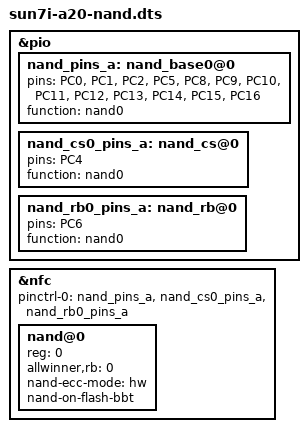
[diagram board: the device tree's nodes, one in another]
/dts-v1/;
/plugin/;

/ {
	fragment@0 {
		target = <&pio>;
		__overlay__ {
			nand_pins_a: nand_base0@0 {
				pins = "PC0", "PC1", "PC2",
					"PC5", "PC8", "PC9", "PC10",
					"PC11", "PC12", "PC13", "PC14",
					"PC15", "PC16";
				function = "nand0";
			};

			nand_cs0_pins_a: nand_cs@0 {
				pins = "PC4";
				function = "nand0";
			};

			nand_rb0_pins_a: nand_rb@0 {
				pins = "PC6";
				function = "nand0";
			};
		};
	};

	fragment@1 {
		target = <&nfc>;
		__overlay__ {
			pinctrl-names = "default";
			pinctrl-0 = <&nand_pins_a>, <&nand_cs0_pins_a>, <&nand_rb0_pins_a>;
			status = "okay";

			nand@0 {
				#address-cells = <2>;
				#size-cells = <2>;
				reg = <0>;
				allwinner,rb = <0>;

				nand-ecc-mode = "hw";
				nand-on-flash-bbt;
			};
		};
	};
};
